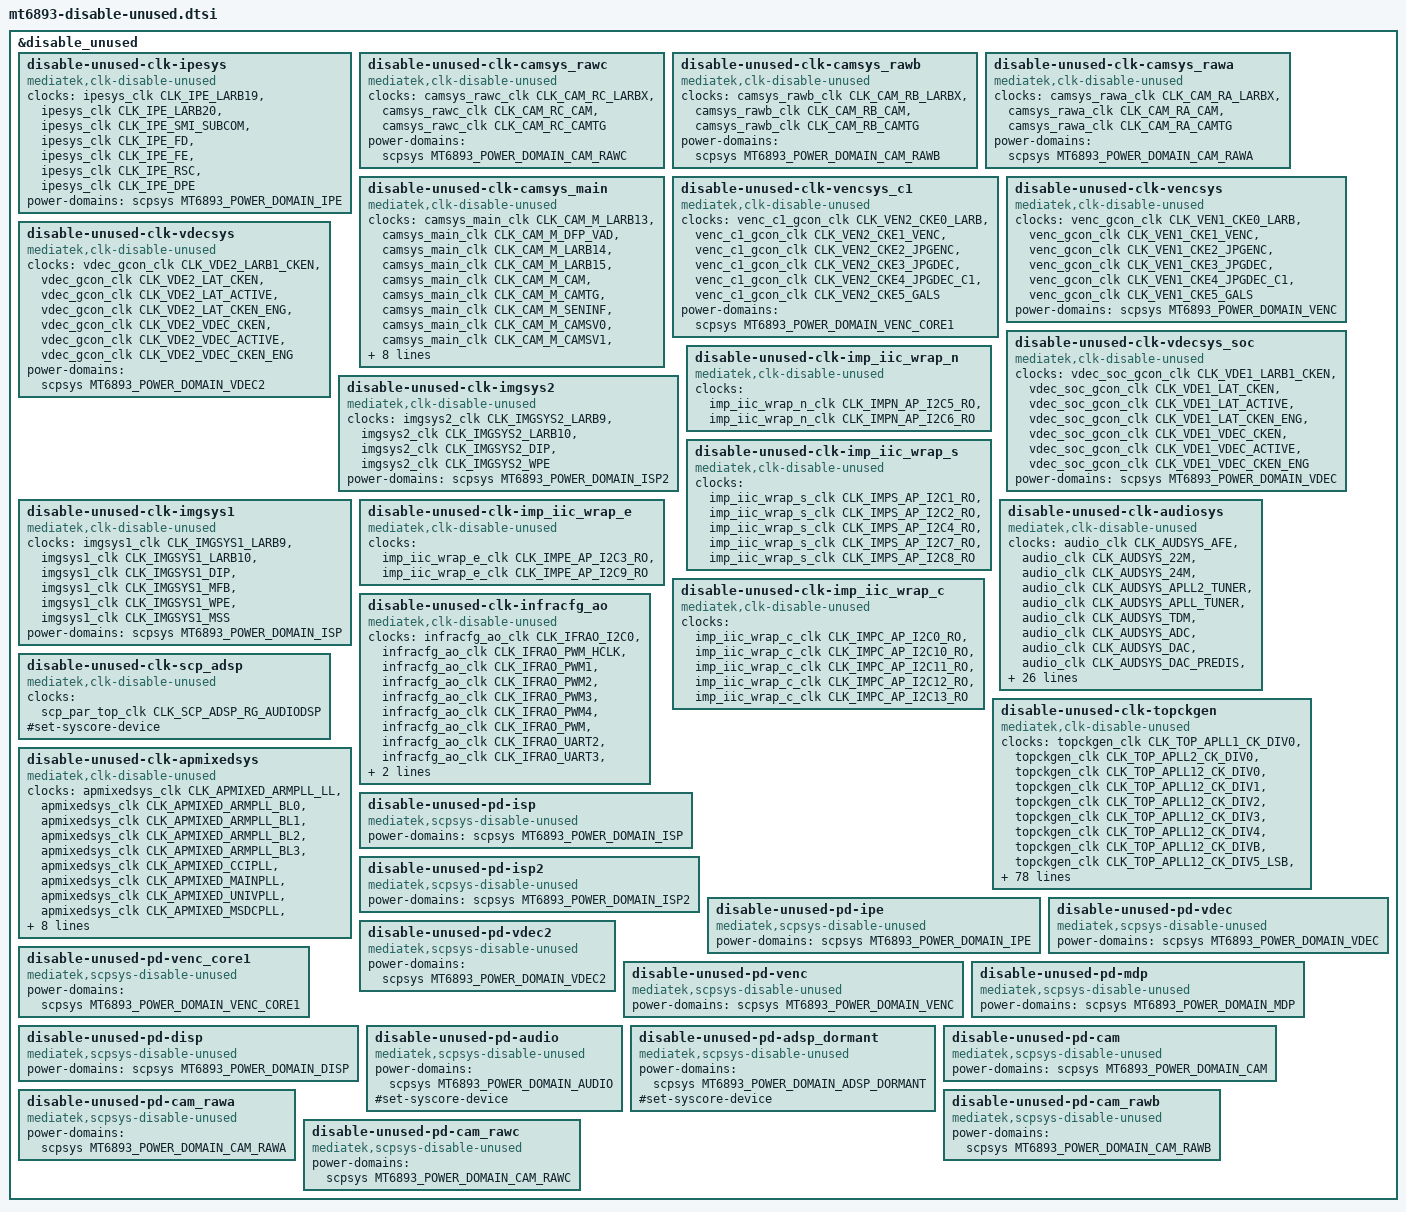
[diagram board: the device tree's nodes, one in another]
// SPDX-License-Identifier: (GPL-2.0 OR MIT)
/*
 * Copyright (C) 2021 MediaTek Inc.
 * Author: Owen Chen <owen.chen@mediatek.com>
 */

&disable_unused {
	status = "okay";

	disable-unused-clk-ipesys {
		compatible = "mediatek,clk-disable-unused";
		clocks =
			<&ipesys_clk CLK_IPE_LARB19>,
			<&ipesys_clk CLK_IPE_LARB20>,
			<&ipesys_clk CLK_IPE_SMI_SUBCOM>,
			<&ipesys_clk CLK_IPE_FD>,
			<&ipesys_clk CLK_IPE_FE>,
			<&ipesys_clk CLK_IPE_RSC>,
			<&ipesys_clk CLK_IPE_DPE>;
			power-domains = <&scpsys MT6893_POWER_DOMAIN_IPE>;
	};

	disable-unused-clk-camsys_rawc {
		compatible = "mediatek,clk-disable-unused";
		clocks =
			<&camsys_rawc_clk CLK_CAM_RC_LARBX>,
			<&camsys_rawc_clk CLK_CAM_RC_CAM>,
			<&camsys_rawc_clk CLK_CAM_RC_CAMTG>;
			power-domains = <&scpsys MT6893_POWER_DOMAIN_CAM_RAWC>;
	};

	disable-unused-clk-camsys_rawb {
		compatible = "mediatek,clk-disable-unused";
		clocks =
			<&camsys_rawb_clk CLK_CAM_RB_LARBX>,
			<&camsys_rawb_clk CLK_CAM_RB_CAM>,
			<&camsys_rawb_clk CLK_CAM_RB_CAMTG>;
			power-domains = <&scpsys MT6893_POWER_DOMAIN_CAM_RAWB>;
	};

	disable-unused-clk-camsys_rawa {
		compatible = "mediatek,clk-disable-unused";
		clocks =
			<&camsys_rawa_clk CLK_CAM_RA_LARBX>,
			<&camsys_rawa_clk CLK_CAM_RA_CAM>,
			<&camsys_rawa_clk CLK_CAM_RA_CAMTG>;
			power-domains = <&scpsys MT6893_POWER_DOMAIN_CAM_RAWA>;
	};

	disable-unused-clk-camsys_main {
		compatible = "mediatek,clk-disable-unused";
		clocks =
			<&camsys_main_clk CLK_CAM_M_LARB13>,
			<&camsys_main_clk CLK_CAM_M_DFP_VAD>,
			<&camsys_main_clk CLK_CAM_M_LARB14>,
			<&camsys_main_clk CLK_CAM_M_LARB15>,
			<&camsys_main_clk CLK_CAM_M_CAM>,
			<&camsys_main_clk CLK_CAM_M_CAMTG>,
			<&camsys_main_clk CLK_CAM_M_SENINF>,
			<&camsys_main_clk CLK_CAM_M_CAMSV0>,
			<&camsys_main_clk CLK_CAM_M_CAMSV1>,
			<&camsys_main_clk CLK_CAM_M_CAMSV2>,
			<&camsys_main_clk CLK_CAM_M_CAMSV3>,
			<&camsys_main_clk CLK_CAM_M_CCU0>,
			<&camsys_main_clk CLK_CAM_M_CCU1>,
			<&camsys_main_clk CLK_CAM_M_MRAW0>,
			<&camsys_main_clk CLK_CAM_M_MRAW1>,
			<&camsys_main_clk CLK_CAM_M_FAKE_ENG>;
			power-domains = <&scpsys MT6893_POWER_DOMAIN_CAM>;
	};

	disable-unused-clk-vencsys_c1 {
		compatible = "mediatek,clk-disable-unused";
		clocks =
			<&venc_c1_gcon_clk CLK_VEN2_CKE0_LARB>,
			<&venc_c1_gcon_clk CLK_VEN2_CKE1_VENC>,
			<&venc_c1_gcon_clk CLK_VEN2_CKE2_JPGENC>,
			<&venc_c1_gcon_clk CLK_VEN2_CKE3_JPGDEC>,
			<&venc_c1_gcon_clk CLK_VEN2_CKE4_JPGDEC_C1>,
			<&venc_c1_gcon_clk CLK_VEN2_CKE5_GALS>;
			power-domains = <&scpsys MT6893_POWER_DOMAIN_VENC_CORE1>;
	};

	disable-unused-clk-vencsys {
		compatible = "mediatek,clk-disable-unused";
		clocks =
			<&venc_gcon_clk CLK_VEN1_CKE0_LARB>,
			<&venc_gcon_clk CLK_VEN1_CKE1_VENC>,
			<&venc_gcon_clk CLK_VEN1_CKE2_JPGENC>,
			<&venc_gcon_clk CLK_VEN1_CKE3_JPGDEC>,
			<&venc_gcon_clk CLK_VEN1_CKE4_JPGDEC_C1>,
			<&venc_gcon_clk CLK_VEN1_CKE5_GALS>;
			power-domains = <&scpsys MT6893_POWER_DOMAIN_VENC>;
	};

	disable-unused-clk-vdecsys {
		compatible = "mediatek,clk-disable-unused";
		clocks =
			<&vdec_gcon_clk CLK_VDE2_LARB1_CKEN>,
			<&vdec_gcon_clk CLK_VDE2_LAT_CKEN>,
			<&vdec_gcon_clk CLK_VDE2_LAT_ACTIVE>,
			<&vdec_gcon_clk CLK_VDE2_LAT_CKEN_ENG>,
			<&vdec_gcon_clk CLK_VDE2_VDEC_CKEN>,
			<&vdec_gcon_clk CLK_VDE2_VDEC_ACTIVE>,
			<&vdec_gcon_clk CLK_VDE2_VDEC_CKEN_ENG>;
			power-domains = <&scpsys MT6893_POWER_DOMAIN_VDEC2>;
	};

	disable-unused-clk-vdecsys_soc {
		compatible = "mediatek,clk-disable-unused";
		clocks =
			<&vdec_soc_gcon_clk CLK_VDE1_LARB1_CKEN>,
			<&vdec_soc_gcon_clk CLK_VDE1_LAT_CKEN>,
			<&vdec_soc_gcon_clk CLK_VDE1_LAT_ACTIVE>,
			<&vdec_soc_gcon_clk CLK_VDE1_LAT_CKEN_ENG>,
			<&vdec_soc_gcon_clk CLK_VDE1_VDEC_CKEN>,
			<&vdec_soc_gcon_clk CLK_VDE1_VDEC_ACTIVE>,
			<&vdec_soc_gcon_clk CLK_VDE1_VDEC_CKEN_ENG>;
			power-domains = <&scpsys MT6893_POWER_DOMAIN_VDEC>;
	};

	disable-unused-clk-imgsys2 {
		compatible = "mediatek,clk-disable-unused";
		clocks =
			<&imgsys2_clk CLK_IMGSYS2_LARB9>,
			<&imgsys2_clk CLK_IMGSYS2_LARB10>,
			<&imgsys2_clk CLK_IMGSYS2_DIP>,
			<&imgsys2_clk CLK_IMGSYS2_WPE>;
			power-domains = <&scpsys MT6893_POWER_DOMAIN_ISP2>;
	};

	disable-unused-clk-imgsys1 {
		compatible = "mediatek,clk-disable-unused";
		clocks =
			<&imgsys1_clk CLK_IMGSYS1_LARB9>,
			<&imgsys1_clk CLK_IMGSYS1_LARB10>,
			<&imgsys1_clk CLK_IMGSYS1_DIP>,
			<&imgsys1_clk CLK_IMGSYS1_MFB>,
			<&imgsys1_clk CLK_IMGSYS1_WPE>,
			<&imgsys1_clk CLK_IMGSYS1_MSS>;
			power-domains = <&scpsys MT6893_POWER_DOMAIN_ISP>;
	};

	disable-unused-clk-imp_iic_wrap_n {
		compatible = "mediatek,clk-disable-unused";
		clocks =
			<&imp_iic_wrap_n_clk CLK_IMPN_AP_I2C5_RO>,
			<&imp_iic_wrap_n_clk CLK_IMPN_AP_I2C6_RO>;
	};

	disable-unused-clk-imp_iic_wrap_s {
		compatible = "mediatek,clk-disable-unused";
		clocks =
			<&imp_iic_wrap_s_clk CLK_IMPS_AP_I2C1_RO>,
			<&imp_iic_wrap_s_clk CLK_IMPS_AP_I2C2_RO>,
			<&imp_iic_wrap_s_clk CLK_IMPS_AP_I2C4_RO>,
			<&imp_iic_wrap_s_clk CLK_IMPS_AP_I2C7_RO>,
			<&imp_iic_wrap_s_clk CLK_IMPS_AP_I2C8_RO>;
	};

	disable-unused-clk-imp_iic_wrap_e {
		compatible = "mediatek,clk-disable-unused";
		clocks =
			<&imp_iic_wrap_e_clk CLK_IMPE_AP_I2C3_RO>,
			<&imp_iic_wrap_e_clk CLK_IMPE_AP_I2C9_RO>;
	};

	disable-unused-clk-audiosys {
		compatible = "mediatek,clk-disable-unused";
		clocks =
			<&audio_clk CLK_AUDSYS_AFE>,
			<&audio_clk CLK_AUDSYS_22M>,
			<&audio_clk CLK_AUDSYS_24M>,
			<&audio_clk CLK_AUDSYS_APLL2_TUNER>,
			<&audio_clk CLK_AUDSYS_APLL_TUNER>,
			<&audio_clk CLK_AUDSYS_TDM>,
			<&audio_clk CLK_AUDSYS_ADC>,
			<&audio_clk CLK_AUDSYS_DAC>,
			<&audio_clk CLK_AUDSYS_DAC_PREDIS>,
			<&audio_clk CLK_AUDSYS_TML>,
			<&audio_clk CLK_AUDSYS_NLE>,
			<&audio_clk CLK_AUDSYS_I2S1_BCLK>,
			<&audio_clk CLK_AUDSYS_I2S2_BCLK>,
			<&audio_clk CLK_AUDSYS_I2S3_BCLK>,
			<&audio_clk CLK_AUDSYS_I2S4_BCLK>,
			<&audio_clk CLK_AUDSYS_CONNSYS_I2S_ASRC>,
			<&audio_clk CLK_AUDSYS_GENERAL1_ASRC>,
			<&audio_clk CLK_AUDSYS_GENERAL2_ASRC>,
			<&audio_clk CLK_AUDSYS_DAC_HIRES>,
			<&audio_clk CLK_AUDSYS_ADC_HIRES>,
			<&audio_clk CLK_AUDSYS_ADC_HIRES_TML>,
			<&audio_clk CLK_AUDSYS_ADDA6_ADC>,
			<&audio_clk CLK_AUDSYS_ADDA6_ADC_HIRES>,
			<&audio_clk CLK_AUDSYS_3RD_DAC>,
			<&audio_clk CLK_AUDSYS_3RD_DAC_PREDIS>,
			<&audio_clk CLK_AUDSYS_3RD_DAC_TML>,
			<&audio_clk CLK_AUDSYS_3RD_DAC_HIRES>,
			<&audio_clk CLK_AUDSYS_I2S5_BCLK>,
			<&audio_clk CLK_AUDSYS_I2S6_BCLK>,
			<&audio_clk CLK_AUDSYS_I2S7_BCLK>,
			<&audio_clk CLK_AUDSYS_I2S8_BCLK>,
			<&audio_clk CLK_AUDSYS_I2S9_BCLK>;
			power-domains = <&scpsys MT6893_POWER_DOMAIN_AUDIO>;
			#set-syscore-device;
	};

	disable-unused-clk-imp_iic_wrap_c {
		compatible = "mediatek,clk-disable-unused";
		clocks =
			<&imp_iic_wrap_c_clk CLK_IMPC_AP_I2C0_RO>,
			<&imp_iic_wrap_c_clk CLK_IMPC_AP_I2C10_RO>,
			<&imp_iic_wrap_c_clk CLK_IMPC_AP_I2C11_RO>,
			<&imp_iic_wrap_c_clk CLK_IMPC_AP_I2C12_RO>,
			<&imp_iic_wrap_c_clk CLK_IMPC_AP_I2C13_RO>;
	};

	disable-unused-clk-scp_adsp {
		compatible = "mediatek,clk-disable-unused";
		clocks =
			<&scp_par_top_clk CLK_SCP_ADSP_RG_AUDIODSP>;
		#set-syscore-device;
	};

	disable-unused-clk-infracfg_ao {
		compatible = "mediatek,clk-disable-unused";
		clocks =
			<&infracfg_ao_clk CLK_IFRAO_I2C0>,
			<&infracfg_ao_clk CLK_IFRAO_PWM_HCLK>,
			<&infracfg_ao_clk CLK_IFRAO_PWM1>,
			<&infracfg_ao_clk CLK_IFRAO_PWM2>,
			<&infracfg_ao_clk CLK_IFRAO_PWM3>,
			<&infracfg_ao_clk CLK_IFRAO_PWM4>,
			<&infracfg_ao_clk CLK_IFRAO_PWM>,
			<&infracfg_ao_clk CLK_IFRAO_UART2>,
			<&infracfg_ao_clk CLK_IFRAO_UART3>,
			<&infracfg_ao_clk CLK_IFRAO_CPUM>,
			<&infracfg_ao_clk CLK_IFRAO_MSDC1_SRC>;
	};

	disable-unused-clk-topckgen {
		compatible = "mediatek,clk-disable-unused";
		clocks =
			<&topckgen_clk CLK_TOP_APLL1_CK_DIV0>,
			<&topckgen_clk CLK_TOP_APLL2_CK_DIV0>,
			<&topckgen_clk CLK_TOP_APLL12_CK_DIV0>,
			<&topckgen_clk CLK_TOP_APLL12_CK_DIV1>,
			<&topckgen_clk CLK_TOP_APLL12_CK_DIV2>,
			<&topckgen_clk CLK_TOP_APLL12_CK_DIV3>,
			<&topckgen_clk CLK_TOP_APLL12_CK_DIV4>,
			<&topckgen_clk CLK_TOP_APLL12_CK_DIVB>,
			<&topckgen_clk CLK_TOP_APLL12_CK_DIV5_LSB>,
			<&topckgen_clk CLK_TOP_APLL12_CK_DIV5_MSB>,
			<&topckgen_clk CLK_TOP_APLL12_CK_DIV6>,
			<&topckgen_clk CLK_TOP_APLL12_CK_DIV7>,
			<&topckgen_clk CLK_TOP_APLL12_CK_DIV8>,
			<&topckgen_clk CLK_TOP_APLL12_CK_DIV9>,
			<&topckgen_clk CLK_TOP_AXI_SEL>,
			<&topckgen_clk CLK_TOP_SPM_SEL>,
			<&topckgen_clk CLK_TOP_BUS_AXIMEM_SEL>,
			<&topckgen_clk CLK_TOP_DISP_SEL>,
			<&topckgen_clk CLK_TOP_MDP_SEL>,
			<&topckgen_clk CLK_TOP_IMG1_SEL>,
			<&topckgen_clk CLK_TOP_IMG2_SEL>,
			<&topckgen_clk CLK_TOP_IPE_SEL>,
			<&topckgen_clk CLK_TOP_DPE_SEL>,
			<&topckgen_clk CLK_TOP_CAM_SEL>,
			<&topckgen_clk CLK_TOP_CCU_SEL>,
			<&topckgen_clk CLK_TOP_DSP_SEL>,
			<&topckgen_clk CLK_TOP_DSP1_SEL>,
			<&topckgen_clk CLK_TOP_DSP2_SEL>,
			<&topckgen_clk CLK_TOP_DSP3_SEL>,
			<&topckgen_clk CLK_TOP_DSP4_SEL>,
			<&topckgen_clk CLK_TOP_DSP5_SEL>,
			<&topckgen_clk CLK_TOP_DSP6_SEL>,
			<&topckgen_clk CLK_TOP_DSP7_SEL>,
			<&topckgen_clk CLK_TOP_IPU_IF_SEL>,
			<&topckgen_clk CLK_TOP_MFG_SEL>,
			<&topckgen_clk CLK_TOP_CAMTG_SEL>,
			<&topckgen_clk CLK_TOP_CAMTG2_SEL>,
			<&topckgen_clk CLK_TOP_CAMTG3_SEL>,
			<&topckgen_clk CLK_TOP_CAMTG4_SEL>,
			<&topckgen_clk CLK_TOP_UART_SEL>,
			<&topckgen_clk CLK_TOP_SPI_SEL>,
			<&topckgen_clk CLK_TOP_MSDC50_0_HCLK_SEL>,
			<&topckgen_clk CLK_TOP_MSDC50_0_SEL>,
			<&topckgen_clk CLK_TOP_MSDC30_1_SEL>,
			<&topckgen_clk CLK_TOP_AUDIO_SEL>,
			<&topckgen_clk CLK_TOP_AUD_INTBUS_SEL>,
			<&topckgen_clk CLK_TOP_PWRAP_ULPOSC_SEL>,
			<&topckgen_clk CLK_TOP_ATB_SEL>,
			<&topckgen_clk CLK_TOP_SSPM_SEL>,
			<&topckgen_clk CLK_TOP_DP_SEL>,
			<&topckgen_clk CLK_TOP_SCAM_SEL>,
			<&topckgen_clk CLK_TOP_DISP_PWM_SEL>,
			<&topckgen_clk CLK_TOP_I2C_SEL>,
			<&topckgen_clk CLK_TOP_SENINF_SEL>,
			<&topckgen_clk CLK_TOP_SENINF1_SEL>,
			<&topckgen_clk CLK_TOP_SENINF2_SEL>,
			<&topckgen_clk CLK_TOP_SENINF3_SEL>,
			<&topckgen_clk CLK_TOP_DXCC_SEL>,
			<&topckgen_clk CLK_TOP_AUD_ENGEN1_SEL>,
			<&topckgen_clk CLK_TOP_AUD_ENGEN2_SEL>,
			<&topckgen_clk CLK_TOP_AES_UFSFDE_SEL>,
			<&topckgen_clk CLK_TOP_UFS_SEL>,
			<&topckgen_clk CLK_TOP_AUD_1_SEL>,
			<&topckgen_clk CLK_TOP_AUD_2_SEL>,
			<&topckgen_clk CLK_TOP_ADSP_SEL>,
			<&topckgen_clk CLK_TOP_DPMAIF_MAIN_SEL>,
			<&topckgen_clk CLK_TOP_VENC_SEL>,
			<&topckgen_clk CLK_TOP_VDEC_SEL>,
			<&topckgen_clk CLK_TOP_VDEC_LAT_SEL>,
			<&topckgen_clk CLK_TOP_CAMTM_SEL>,
			<&topckgen_clk CLK_TOP_PWM_SEL>,
			<&topckgen_clk CLK_TOP_AUDIO_H_SEL>,
			<&topckgen_clk CLK_TOP_CAMTG5_SEL>,
			<&topckgen_clk CLK_TOP_CAMTG6_SEL>,
			<&topckgen_clk CLK_TOP_MCUPM_SEL>,
			<&topckgen_clk CLK_TOP_SPMI_MST_SEL>,
			<&topckgen_clk CLK_TOP_DVFSRC_SEL>,
			<&topckgen_clk CLK_TOP_APLL_I2S0_MCK_SEL>,
			<&topckgen_clk CLK_TOP_APLL_I2S1_MCK_SEL>,
			<&topckgen_clk CLK_TOP_APLL_I2S2_MCK_SEL>,
			<&topckgen_clk CLK_TOP_APLL_I2S3_MCK_SEL>,
			<&topckgen_clk CLK_TOP_APLL_I2S4_MCK_SEL>,
			<&topckgen_clk CLK_TOP_APLL_I2S5_MCK_SEL>,
			<&topckgen_clk CLK_TOP_APLL_I2S6_MCK_SEL>,
			<&topckgen_clk CLK_TOP_APLL_I2S7_MCK_SEL>,
			<&topckgen_clk CLK_TOP_APLL_I2S8_MCK_SEL>,
			<&topckgen_clk CLK_TOP_APLL_I2S9_MCK_SEL>;
	};

	disable-unused-clk-apmixedsys {
		compatible = "mediatek,clk-disable-unused";
		clocks =
			<&apmixedsys_clk CLK_APMIXED_ARMPLL_LL>,
			<&apmixedsys_clk CLK_APMIXED_ARMPLL_BL0>,
			<&apmixedsys_clk CLK_APMIXED_ARMPLL_BL1>,
			<&apmixedsys_clk CLK_APMIXED_ARMPLL_BL2>,
			<&apmixedsys_clk CLK_APMIXED_ARMPLL_BL3>,
			<&apmixedsys_clk CLK_APMIXED_CCIPLL>,
			<&apmixedsys_clk CLK_APMIXED_MAINPLL>,
			<&apmixedsys_clk CLK_APMIXED_UNIVPLL>,
			<&apmixedsys_clk CLK_APMIXED_MSDCPLL>,
			<&apmixedsys_clk CLK_APMIXED_MMPLL>,
			<&apmixedsys_clk CLK_APMIXED_ADSPPLL>,
			<&apmixedsys_clk CLK_APMIXED_MFGPLL>,
			<&apmixedsys_clk CLK_APMIXED_TVDPLL>,
			<&apmixedsys_clk CLK_APMIXED_APLL1>,
			<&apmixedsys_clk CLK_APMIXED_APLL2>,
			<&apmixedsys_clk CLK_APMIXED_MPLL>,
			<&apmixedsys_clk CLK_APMIXED_APUPLL>;
	};

	disable-unused-pd-isp {
		compatible = "mediatek,scpsys-disable-unused";
		power-domains = <&scpsys MT6893_POWER_DOMAIN_ISP>;
	};

	disable-unused-pd-isp2 {
		compatible = "mediatek,scpsys-disable-unused";
		power-domains = <&scpsys MT6893_POWER_DOMAIN_ISP2>;
	};

	disable-unused-pd-ipe {
		compatible = "mediatek,scpsys-disable-unused";
		power-domains = <&scpsys MT6893_POWER_DOMAIN_IPE>;
	};

	disable-unused-pd-vdec {
		compatible = "mediatek,scpsys-disable-unused";
		power-domains = <&scpsys MT6893_POWER_DOMAIN_VDEC>;
	};

	disable-unused-pd-vdec2 {
		compatible = "mediatek,scpsys-disable-unused";
		power-domains = <&scpsys MT6893_POWER_DOMAIN_VDEC2>;
	};

	disable-unused-pd-venc {
		compatible = "mediatek,scpsys-disable-unused";
		power-domains = <&scpsys MT6893_POWER_DOMAIN_VENC>;
	};

	disable-unused-pd-venc_core1 {
		compatible = "mediatek,scpsys-disable-unused";
		power-domains = <&scpsys MT6893_POWER_DOMAIN_VENC_CORE1>;
	};

	disable-unused-pd-mdp {
		compatible = "mediatek,scpsys-disable-unused";
		power-domains = <&scpsys MT6893_POWER_DOMAIN_MDP>;
	};

	disable-unused-pd-disp {
		compatible = "mediatek,scpsys-disable-unused";
		power-domains = <&scpsys MT6893_POWER_DOMAIN_DISP>;
	};

	disable-unused-pd-audio {
		compatible = "mediatek,scpsys-disable-unused";
		power-domains = <&scpsys MT6893_POWER_DOMAIN_AUDIO>;
		#set-syscore-device;
	};

	disable-unused-pd-adsp_dormant {
		compatible = "mediatek,scpsys-disable-unused";
		power-domains = <&scpsys MT6893_POWER_DOMAIN_ADSP_DORMANT>;
		#set-syscore-device;
	};

	disable-unused-pd-cam {
		compatible = "mediatek,scpsys-disable-unused";
		power-domains = <&scpsys MT6893_POWER_DOMAIN_CAM>;
	};

	disable-unused-pd-cam_rawa {
		compatible = "mediatek,scpsys-disable-unused";
		power-domains = <&scpsys MT6893_POWER_DOMAIN_CAM_RAWA>;
	};

	disable-unused-pd-cam_rawb {
		compatible = "mediatek,scpsys-disable-unused";
		power-domains = <&scpsys MT6893_POWER_DOMAIN_CAM_RAWB>;
	};

	disable-unused-pd-cam_rawc {
		compatible = "mediatek,scpsys-disable-unused";
		power-domains = <&scpsys MT6893_POWER_DOMAIN_CAM_RAWC>;
	};
};
